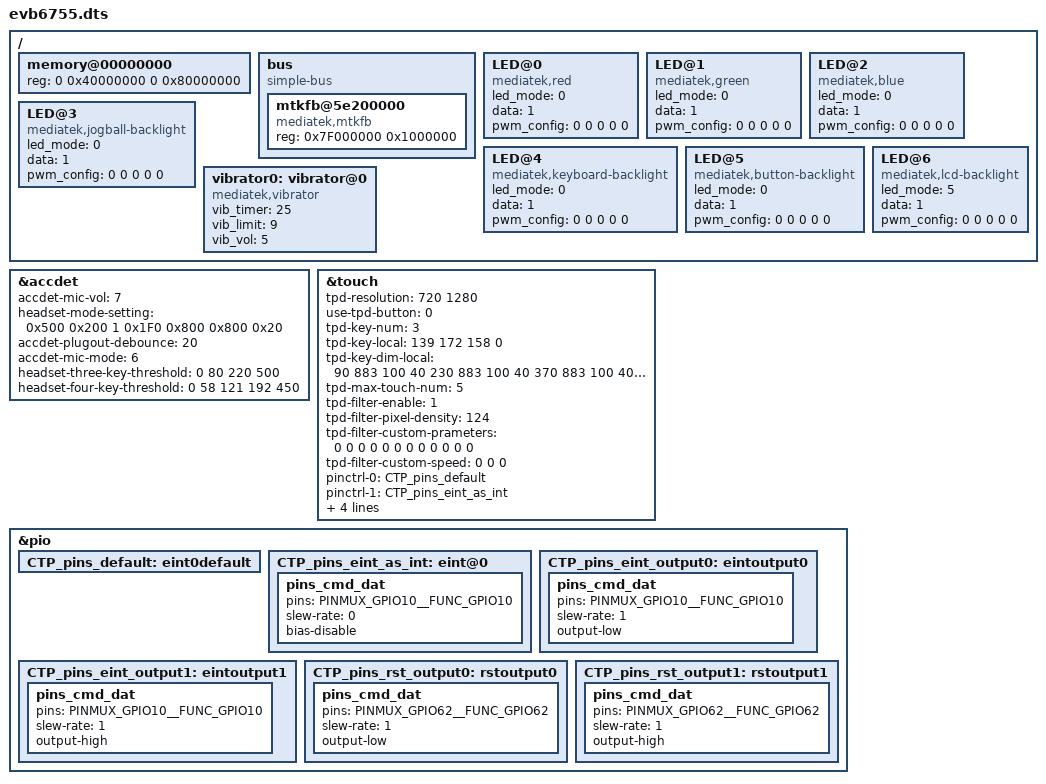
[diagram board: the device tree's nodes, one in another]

/dts-v1/;

#include "mt6755.dtsi"

/ {
	memory@00000000 {
		device_type = "memory";
		reg = <0 0x40000000 0 0x80000000>;
	};

	bus {
		compatible = "simple-bus";
		#address-cells = <1>;
		#size-cells = <1>;
		ranges = <0 0 0 0xffffffff>;

		mtkfb@5e200000 {
			compatible = "mediatek,mtkfb";
			reg = <0x7F000000 0x1000000>;
		};

	};
	LED@0 {
		compatible = "mediatek,red";
		led_mode = <0>;
		data = <1>;
		pwm_config = <0 0 0 0 0>;
	};
	LED@1 {
		compatible = "mediatek,green";
		led_mode = <0>;
		data = <1>;
		pwm_config = <0 0 0 0 0>;
	};
	LED@2 {
		compatible = "mediatek,blue";
		led_mode = <0>;
		data = <1>;
		pwm_config = <0 0 0 0 0>;
	};
	LED@3 {
		compatible = "mediatek,jogball-backlight";
		led_mode = <0>;
		data = <1>;
		pwm_config = <0 0 0 0 0>;
	};
	LED@4 {
		compatible = "mediatek,keyboard-backlight";
		led_mode = <0>;
		data = <1>;
		pwm_config = <0 0 0 0 0>;
	};
	LED@5 {
		compatible = "mediatek,button-backlight";
		led_mode = <0>;
		data = <1>;
		pwm_config = <0 0 0 0 0>;
	};
	LED@6 {
		compatible = "mediatek,lcd-backlight";
		led_mode = <5>;
		data = <1>;
		pwm_config = <0 0 0 0 0>;
	};
	vibrator0:vibrator@0 {
		compatible = "mediatek,vibrator";
		vib_timer = <25>;
		vib_limit = <9>;
		vib_vol= <5>;
	};
};
&accdet {
		accdet-mic-vol = <7>;
		headset-mode-setting = <0x500 0x200 1 0x1F0 0x800 0x800 0x20>;
		accdet-plugout-debounce = <20>;
		/*1:ACC mode, 2:low cost without in bias, 6:low cost with in bias*/
		accdet-mic-mode = <6>;
		/*0--MD_MAX--UP_MAX--DW_MAX*/
		headset-three-key-threshold = <0 80 220 500>;
		/*0--MD_MAX--VOICE_MAX--UP_MAX--DW_MAX*/
		headset-four-key-threshold = <0 58 121 192 450>;
};
&touch {
	tpd-resolution = <720 1280>;
	use-tpd-button = <0>;
	tpd-key-num = <3>;
	tpd-key-local= <139 172 158 0>;
	tpd-key-dim-local = <90 883 100 40 230 883 100 40 370 883 100 40 0 0 0 0>;
	tpd-max-touch-num = <5>;
	tpd-filter-enable = <1>;
	tpd-filter-pixel-density = <124>;
	tpd-filter-custom-prameters = <0 0 0 0 0 0 0 0 0 0 0 0>;
	tpd-filter-custom-speed = <0 0 0>;
	pinctrl-names = "default", "state_eint_as_int", "state_eint_output0", "state_eint_output1",
		"state_rst_output0", "state_rst_output1";
	pinctrl-0 = <&CTP_pins_default>;
	pinctrl-1 = <&CTP_pins_eint_as_int>;
	pinctrl-2 = <&CTP_pins_eint_output0>;
	pinctrl-3 = <&CTP_pins_eint_output1>;
	pinctrl-4 = <&CTP_pins_rst_output0>;
	pinctrl-5 = <&CTP_pins_rst_output1>;
	status = "okay";
};
&pio {
	CTP_pins_default: eint0default {
	};
	CTP_pins_eint_as_int: eint@0 {
		pins_cmd_dat {
			pins = <PINMUX_GPIO10__FUNC_GPIO10>;
			slew-rate = <0>;
			bias-disable;
		};
	};
	CTP_pins_eint_output0: eintoutput0 {
		pins_cmd_dat {
			pins = <PINMUX_GPIO10__FUNC_GPIO10>;
			slew-rate = <1>;
			output-low;
		};
	};
	CTP_pins_eint_output1: eintoutput1 {
		pins_cmd_dat {
			pins = <PINMUX_GPIO10__FUNC_GPIO10>;
			slew-rate = <1>;
			output-high;
		};
	};
	CTP_pins_rst_output0: rstoutput0 {
		pins_cmd_dat {
			pins = <PINMUX_GPIO62__FUNC_GPIO62>;
			slew-rate = <1>;
			output-low;
		};
	};
	CTP_pins_rst_output1: rstoutput1 {
		pins_cmd_dat {
			pins = <PINMUX_GPIO62__FUNC_GPIO62>;
			slew-rate = <1>;
			output-high;
		};
	};
};
/* TOUCH end */
